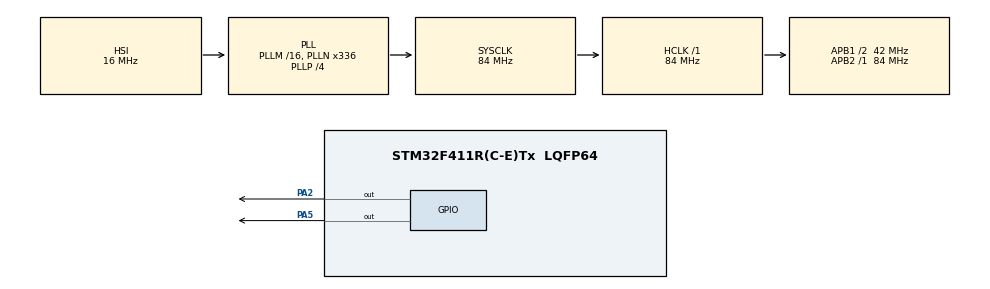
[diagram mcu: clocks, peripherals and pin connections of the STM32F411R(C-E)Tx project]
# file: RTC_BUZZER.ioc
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Mcu.Family=STM32F4
Mcu.Name=STM32F411R(C-E)Tx
Mcu.Package=LQFP64
NVIC.PriorityGroup=NVIC_PRIORITYGROUP_0
NVIC.RTC_Alarm_IRQn=true\:0\:0\:false\:false\:true\:true\:true\:true
NVIC.TIM2_IRQn=true\:0\:0\:false\:false\:true\:true\:true\:true
PA2.Signal=GPIO_Output
PA5.Signal=GPIO_Output
PC14-OSC32_IN.Mode=LSE-External-Oscillator
PC14-OSC32_IN.Signal=RCC_OSC32_IN
PC15-OSC32_OUT.Mode=LSE-External-Oscillator
PC15-OSC32_OUT.Signal=RCC_OSC32_OUT
ProjectManager.HeapSize=0x200
ProjectManager.StackSize=0x400
ProjectManager.TargetToolchain=STM32CubeIDE
RCC.48MHZClocksFreq_Value=84000000
RCC.AHBFreq_Value=84000000
RCC.APB1CLKDivider=RCC_HCLK_DIV2
RCC.APB1Freq_Value=42000000
RCC.APB1TimFreq_Value=84000000
RCC.APB2Freq_Value=84000000
RCC.APB2TimFreq_Value=84000000
RCC.CortexFreq_Value=84000000
RCC.FLatency-AdvancedSettings=FLASH_LATENCY_2
RCC.HCLKFreq_Value=84000000
RCC.HSE_VALUE=8000000
RCC.HSI_VALUE=16000000
RCC.PLLN=336
RCC.PLLP=RCC_PLLP_DIV4
RCC.SYSCLKFreq_VALUE=84000000
RCC.SYSCLKSource=RCC_SYSCLKSOURCE_PLLCLK
RCC.VCOOutputFreq_Value=336000000
RTC.Alarm=RTC_ALARM_A
RTC.Hours=14
RTC.Hours_A=14
RTC.Seconds_A=5
TIM2.AutoReloadPreload=TIM_AUTORELOAD_PRELOAD_ENABLE
TIM2.Period=19999
TIM2.Prescaler=8399
VP_RTC_VS_RTC_Activate.Mode=RTC_Enabled
VP_RTC_VS_RTC_Alarm_A_Intern.Mode=Alarm A
VP_RTC_VS_RTC_Calendar.Mode=RTC_Calendar
VP_TIM2_VS_ClockSourceINT.Mode=Internal
board=NUCLEO-F411RE

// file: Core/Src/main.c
/* USER CODE BEGIN Header */
/**
  ******************************************************************************
  * @file           : main.c
  * @brief          : Main program body
  ******************************************************************************
  * @attention
  *
  * Copyright (c) 2025 STMicroelectronics.
  * All rights reserved.
  *
  * This software is licensed under terms that can be found in the LICENSE file
  * in the root directory of this software component.
  * If no LICENSE file comes with this software, it is provided AS-IS.
  *
  ******************************************************************************
  */
/* USER CODE END Header */
#include "main.h"

RTC_HandleTypeDef hrtc;

TIM_HandleTypeDef htim2;

void SystemClock_Config(void);
static void MX_GPIO_Init(void);
static void MX_RTC_Init(void);
static void MX_TIM2_Init(void);

/* USER CODE BEGIN 0 */
 void HAL_TIM_PeriodElapsedCallback(TIM_HandleTypeDef *htim){
	 HAL_GPIO_WritePin(GPIOA,GPIO_PIN_3,0);
	 HAL_GPIO_WritePin(GPIOA,GPIO_PIN_5,0);
	 HAL_TIM_Base_Stop_IT(&htim2);
}

 void HAL_RTC_AlarmAEventCallback(RTC_HandleTypeDef *hrtc){
	 HAL_GPIO_WritePin(GPIOA,GPIO_PIN_3,1);
	 HAL_GPIO_WritePin(GPIOA,GPIO_PIN_5,1);
	 HAL_TIM_Base_Start_IT(&htim2);

 }

/* USER CODE END 0 */

int main(void)
{

  /* MCU Configuration--------------------------------------------------------*/

  /* Reset of all peripherals, Initializes the Flash interface and the Systick. */
  HAL_Init();

  /* Configure the system clock */
  SystemClock_Config();

  /* Initialize all configured peripherals */
  MX_GPIO_Init();
  MX_RTC_Init();
  MX_TIM2_Init();

  /* Infinite loop */
  while (1)
  {

  }
}

void SystemClock_Config(void)
{
  RCC_OscInitTypeDef RCC_OscInitStruct = {0};
  RCC_ClkInitTypeDef RCC_ClkInitStruct = {0};

  /** Configure the main internal regulator output voltage
  */
  __HAL_RCC_PWR_CLK_ENABLE();
  __HAL_PWR_VOLTAGESCALING_CONFIG(PWR_REGULATOR_VOLTAGE_SCALE1);

  /** Initializes the RCC Oscillators according to the specified parameters
  * in the RCC_OscInitTypeDef structure.
  */
  RCC_OscInitStruct.OscillatorType = RCC_OSCILLATORTYPE_HSI|RCC_OSCILLATORTYPE_LSI;
  RCC_OscInitStruct.HSIState = RCC_HSI_ON;
  RCC_OscInitStruct.HSICalibrationValue = RCC_HSICALIBRATION_DEFAULT;
  RCC_OscInitStruct.LSIState = RCC_LSI_ON;
  RCC_OscInitStruct.PLL.PLLState = RCC_PLL_ON;
  RCC_OscInitStruct.PLL.PLLSource = RCC_PLLSOURCE_HSI;
  RCC_OscInitStruct.PLL.PLLM = 16;
  RCC_OscInitStruct.PLL.PLLN = 336;
  RCC_OscInitStruct.PLL.PLLP = RCC_PLLP_DIV4;
  RCC_OscInitStruct.PLL.PLLQ = 4;
  if (HAL_RCC_OscConfig(&RCC_OscInitStruct) != HAL_OK)
  {
    Error_Handler();
  }

  /** Initializes the CPU, AHB and APB buses clocks
  */
  RCC_ClkInitStruct.ClockType = RCC_CLOCKTYPE_HCLK|RCC_CLOCKTYPE_SYSCLK
                              |RCC_CLOCKTYPE_PCLK1|RCC_CLOCKTYPE_PCLK2;
  RCC_ClkInitStruct.SYSCLKSource = RCC_SYSCLKSOURCE_PLLCLK;
  RCC_ClkInitStruct.AHBCLKDivider = RCC_SYSCLK_DIV1;
  RCC_ClkInitStruct.APB1CLKDivider = RCC_HCLK_DIV2;
  RCC_ClkInitStruct.APB2CLKDivider = RCC_HCLK_DIV1;

  if (HAL_RCC_ClockConfig(&RCC_ClkInitStruct, FLASH_LATENCY_2) != HAL_OK)
  {
    Error_Handler();
  }
}

static void MX_RTC_Init(void)
{

  RTC_TimeTypeDef sTime = {0};
  RTC_DateTypeDef sDate = {0};
  RTC_AlarmTypeDef sAlarm = {0};

  /** Initialize RTC Only
  */
  hrtc.Instance = RTC;
  hrtc.Init.HourFormat = RTC_HOURFORMAT_24;
  hrtc.Init.AsynchPrediv = 127;
  hrtc.Init.SynchPrediv = 255;
  hrtc.Init.OutPut = RTC_OUTPUT_DISABLE;
  hrtc.Init.OutPutPolarity = RTC_OUTPUT_POLARITY_HIGH;
  hrtc.Init.OutPutType = RTC_OUTPUT_TYPE_OPENDRAIN;
  if (HAL_RTC_Init(&hrtc) != HAL_OK)
  {
    Error_Handler();
  }

  /** Initialize RTC and set the Time and Date
  */
  sTime.Hours = 0x14;
  sTime.Minutes = 0x0;
  sTime.Seconds = 0x0;
  sTime.DayLightSaving = RTC_DAYLIGHTSAVING_NONE;
  sTime.StoreOperation = RTC_STOREOPERATION_RESET;
  if (HAL_RTC_SetTime(&hrtc, &sTime, RTC_FORMAT_BCD) != HAL_OK)
  {
    Error_Handler();
  }
  sDate.WeekDay = RTC_WEEKDAY_MONDAY;
  sDate.Month = RTC_MONTH_JANUARY;
  sDate.Date = 0x1;
  sDate.Year = 0x0;

  if (HAL_RTC_SetDate(&hrtc, &sDate, RTC_FORMAT_BCD) != HAL_OK)
  {
    Error_Handler();
  }

  /** Enable the Alarm A
  */
  sAlarm.AlarmTime.Hours = 0x14;
  sAlarm.AlarmTime.Minutes = 0x0;
  sAlarm.AlarmTime.Seconds = 0x5;
  sAlarm.AlarmTime.SubSeconds = 0x0;
  sAlarm.AlarmTime.DayLightSaving = RTC_DAYLIGHTSAVING_NONE;
  sAlarm.AlarmTime.StoreOperation = RTC_STOREOPERATION_RESET;
  sAlarm.AlarmMask = RTC_ALARMMASK_NONE;
  sAlarm.AlarmSubSecondMask = RTC_ALARMSUBSECONDMASK_ALL;
  sAlarm.AlarmDateWeekDaySel = RTC_ALARMDATEWEEKDAYSEL_DATE;
  sAlarm.AlarmDateWeekDay = 0x1;
  sAlarm.Alarm = RTC_ALARM_A;
  if (HAL_RTC_SetAlarm_IT(&hrtc, &sAlarm, RTC_FORMAT_BCD) != HAL_OK)
  {
    Error_Handler();
  }

}

static void MX_TIM2_Init(void)
{

  TIM_ClockConfigTypeDef sClockSourceConfig = {0};
  TIM_MasterConfigTypeDef sMasterConfig = {0};

  htim2.Instance = TIM2;
  htim2.Init.Prescaler = 8399;
  htim2.Init.CounterMode = TIM_COUNTERMODE_UP;
  htim2.Init.Period = 19999;
  htim2.Init.ClockDivision = TIM_CLOCKDIVISION_DIV1;
  htim2.Init.AutoReloadPreload = TIM_AUTORELOAD_PRELOAD_ENABLE;
  if (HAL_TIM_Base_Init(&htim2) != HAL_OK)
  {
    Error_Handler();
  }
  sClockSourceConfig.ClockSource = TIM_CLOCKSOURCE_INTERNAL;
  if (HAL_TIM_ConfigClockSource(&htim2, &sClockSourceConfig) != HAL_OK)
  {
    Error_Handler();
  }
  sMasterConfig.MasterOutputTrigger = TIM_TRGO_RESET;
  sMasterConfig.MasterSlaveMode = TIM_MASTERSLAVEMODE_DISABLE;
  if (HAL_TIMEx_MasterConfigSynchronization(&htim2, &sMasterConfig) != HAL_OK)
  {
    Error_Handler();
  }

}

static void MX_GPIO_Init(void)
{
  GPIO_InitTypeDef GPIO_InitStruct = {0};

  /* GPIO Ports Clock Enable */
  __HAL_RCC_GPIOC_CLK_ENABLE();
  __HAL_RCC_GPIOA_CLK_ENABLE();

  /*Configure GPIO pin Output Level */
  HAL_GPIO_WritePin(GPIOA, GPIO_PIN_2|GPIO_PIN_5, GPIO_PIN_RESET);

  /*Configure GPIO pins : PA2 PA5 */
  GPIO_InitStruct.Pin = GPIO_PIN_2|GPIO_PIN_5;
  GPIO_InitStruct.Mode = GPIO_MODE_OUTPUT_PP;
  GPIO_InitStruct.Pull = GPIO_NOPULL;
  GPIO_InitStruct.Speed = GPIO_SPEED_FREQ_LOW;
  HAL_GPIO_Init(GPIOA, &GPIO_InitStruct);

}

void Error_Handler(void)
{
  __disable_irq();
  while (1)
  {
  }
}
